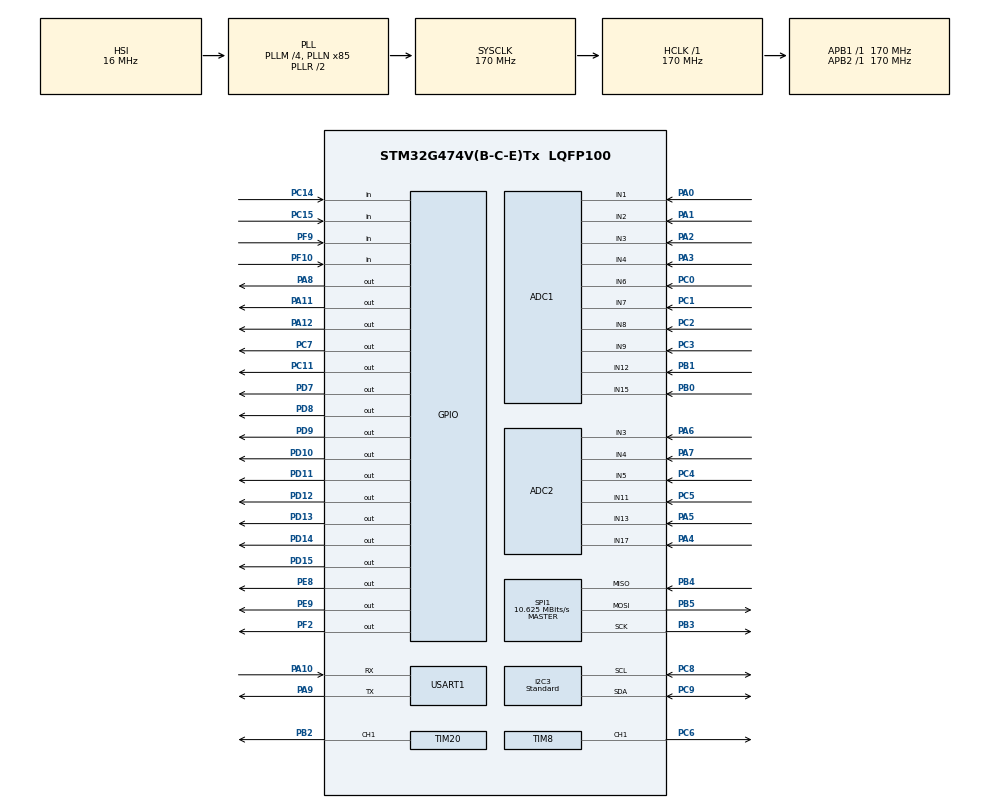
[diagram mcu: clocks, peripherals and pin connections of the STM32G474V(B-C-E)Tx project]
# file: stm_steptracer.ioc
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ADC1.Channel-0\#ChannelRegularConversion=ADC_CHANNEL_6
ADC1.Channel-1\#ChannelRegularConversion=ADC_CHANNEL_8
ADC1.Channel-2\#ChannelRegularConversion=ADC_CHANNEL_7
ADC1.Channel-3\#ChannelRegularConversion=ADC_CHANNEL_9
ADC1.Channel-4\#ChannelRegularConversion=ADC_CHANNEL_2
ADC1.Channel-5\#ChannelRegularConversion=ADC_CHANNEL_1
ADC1.Channel-6\#ChannelRegularConversion=ADC_CHANNEL_4
ADC1.Channel-7\#ChannelRegularConversion=ADC_CHANNEL_3
ADC1.Channel-8\#ChannelRegularConversion=ADC_CHANNEL_12
ADC1.Channel-9\#ChannelRegularConversion=ADC_CHANNEL_15
ADC1.EOCSelection=ADC_EOC_SEQ_CONV
ADC1.NbrOfConversion=10
ADC1.NbrOfConversionFlag=1
ADC1.OffsetNumber-0\#ChannelRegularConversion=ADC_OFFSET_NONE
ADC1.OffsetNumber-1\#ChannelRegularConversion=ADC_OFFSET_NONE
ADC1.OffsetNumber-2\#ChannelRegularConversion=ADC_OFFSET_NONE
ADC1.OffsetNumber-3\#ChannelRegularConversion=ADC_OFFSET_NONE
ADC1.OffsetNumber-4\#ChannelRegularConversion=ADC_OFFSET_NONE
ADC1.OffsetNumber-5\#ChannelRegularConversion=ADC_OFFSET_NONE
ADC1.OffsetNumber-6\#ChannelRegularConversion=ADC_OFFSET_NONE
ADC1.OffsetNumber-7\#ChannelRegularConversion=ADC_OFFSET_NONE
ADC1.OffsetNumber-8\#ChannelRegularConversion=ADC_OFFSET_NONE
ADC1.OffsetNumber-9\#ChannelRegularConversion=ADC_OFFSET_NONE
ADC1.Overrun=ADC_OVR_DATA_OVERWRITTEN
ADC1.Rank-0\#ChannelRegularConversion=1
ADC1.Rank-1\#ChannelRegularConversion=2
ADC1.Rank-2\#ChannelRegularConversion=3
ADC1.Rank-3\#ChannelRegularConversion=4
ADC1.Rank-4\#ChannelRegularConversion=5
ADC1.Rank-5\#ChannelRegularConversion=6
ADC1.Rank-6\#ChannelRegularConversion=7
ADC1.Rank-7\#ChannelRegularConversion=8
ADC1.Rank-8\#ChannelRegularConversion=9
ADC1.Rank-9\#ChannelRegularConversion=10
ADC1.SamplingTime-0\#ChannelRegularConversion=ADC_SAMPLETIME_47CYCLES_5
ADC1.SamplingTime-1\#ChannelRegularConversion=ADC_SAMPLETIME_47CYCLES_5
ADC1.SamplingTime-2\#ChannelRegularConversion=ADC_SAMPLETIME_47CYCLES_5
ADC1.SamplingTime-3\#ChannelRegularConversion=ADC_SAMPLETIME_47CYCLES_5
ADC1.SamplingTime-4\#ChannelRegularConversion=ADC_SAMPLETIME_47CYCLES_5
ADC1.SamplingTime-5\#ChannelRegularConversion=ADC_SAMPLETIME_47CYCLES_5
ADC1.SamplingTime-6\#ChannelRegularConversion=ADC_SAMPLETIME_47CYCLES_5
ADC1.SamplingTime-7\#ChannelRegularConversion=ADC_SAMPLETIME_47CYCLES_5
ADC1.SamplingTime-8\#ChannelRegularConversion=ADC_SAMPLETIME_47CYCLES_5
ADC1.SamplingTime-9\#ChannelRegularConversion=ADC_SAMPLETIME_47CYCLES_5
ADC1.master=1
ADC2.Channel-0\#ChannelRegularConversion=ADC_CHANNEL_13
ADC2.Channel-1\#ChannelRegularConversion=ADC_CHANNEL_17
ADC2.Channel-2\#ChannelRegularConversion=ADC_CHANNEL_4
ADC2.Channel-3\#ChannelRegularConversion=ADC_CHANNEL_3
ADC2.Channel-4\#ChannelRegularConversion=ADC_CHANNEL_11
ADC2.Channel-5\#ChannelRegularConversion=ADC_CHANNEL_5
ADC2.EOCSelection=ADC_EOC_SEQ_CONV
ADC2.NbrOfConversion=6
ADC2.NbrOfConversionFlag=1
ADC2.OffsetNumber-0\#ChannelRegularConversion=ADC_OFFSET_NONE
ADC2.OffsetNumber-1\#ChannelRegularConversion=ADC_OFFSET_NONE
ADC2.OffsetNumber-2\#ChannelRegularConversion=ADC_OFFSET_NONE
ADC2.OffsetNumber-3\#ChannelRegularConversion=ADC_OFFSET_NONE
ADC2.OffsetNumber-4\#ChannelRegularConversion=ADC_OFFSET_NONE
ADC2.OffsetNumber-5\#ChannelRegularConversion=ADC_OFFSET_NONE
ADC2.Overrun=ADC_OVR_DATA_OVERWRITTEN
ADC2.Rank-0\#ChannelRegularConversion=1
ADC2.Rank-1\#ChannelRegularConversion=2
ADC2.Rank-2\#ChannelRegularConversion=3
ADC2.Rank-3\#ChannelRegularConversion=4
ADC2.Rank-4\#ChannelRegularConversion=5
ADC2.Rank-5\#ChannelRegularConversion=6
ADC2.SamplingTime-0\#ChannelRegularConversion=ADC_SAMPLETIME_47CYCLES_5
ADC2.SamplingTime-1\#ChannelRegularConversion=ADC_SAMPLETIME_47CYCLES_5
ADC2.SamplingTime-2\#ChannelRegularConversion=ADC_SAMPLETIME_47CYCLES_5
ADC2.SamplingTime-3\#ChannelRegularConversion=ADC_SAMPLETIME_47CYCLES_5
ADC2.SamplingTime-4\#ChannelRegularConversion=ADC_SAMPLETIME_47CYCLES_5
ADC2.SamplingTime-5\#ChannelRegularConversion=ADC_SAMPLETIME_47CYCLES_5
Dma.ADC1.0.Direction=DMA_PERIPH_TO_MEMORY
Dma.ADC1.0.EventEnable=DISABLE
Dma.ADC1.0.Instance=DMA1_Channel1
Dma.ADC1.0.MemDataAlignment=DMA_MDATAALIGN_HALFWORD
Dma.ADC1.0.MemInc=DMA_MINC_ENABLE
Dma.ADC1.0.Mode=DMA_NORMAL
Dma.ADC1.0.PeriphDataAlignment=DMA_PDATAALIGN_HALFWORD
Dma.ADC1.0.PeriphInc=DMA_PINC_DISABLE
Dma.ADC1.0.Polarity=HAL_DMAMUX_REQ_GEN_RISING
Dma.ADC1.0.Priority=DMA_PRIORITY_HIGH
Dma.ADC1.0.RequestNumber=1
Dma.ADC1.0.SignalID=NONE
Dma.ADC1.0.SyncEnable=DISABLE
Dma.ADC1.0.SyncPolarity=HAL_DMAMUX_SYNC_NO_EVENT
Dma.ADC1.0.SyncRequestNumber=1
Dma.ADC1.0.SyncSignalID=NONE
Dma.ADC2.1.Direction=DMA_PERIPH_TO_MEMORY
Dma.ADC2.1.EventEnable=DISABLE
Dma.ADC2.1.Instance=DMA1_Channel2
Dma.ADC2.1.MemDataAlignment=DMA_MDATAALIGN_HALFWORD
Dma.ADC2.1.MemInc=DMA_MINC_ENABLE
Dma.ADC2.1.Mode=DMA_NORMAL
Dma.ADC2.1.PeriphDataAlignment=DMA_PDATAALIGN_HALFWORD
Dma.ADC2.1.PeriphInc=DMA_PINC_DISABLE
Dma.ADC2.1.Polarity=HAL_DMAMUX_REQ_GEN_RISING
Dma.ADC2.1.Priority=DMA_PRIORITY_LOW
Dma.ADC2.1.RequestNumber=1
Dma.ADC2.1.SignalID=NONE
Dma.ADC2.1.SyncEnable=DISABLE
Dma.ADC2.1.SyncPolarity=HAL_DMAMUX_SYNC_NO_EVENT
Dma.ADC2.1.SyncRequestNumber=1
Dma.ADC2.1.SyncSignalID=NONE
Dma.Request0=ADC1
Dma.Request1=ADC2
I2C3.I2C_Speed_Mode=I2C_Standard
I2C3.Timing=0x40B285C2
Mcu.Family=STM32G4
Mcu.Name=STM32G474V(B-C-E)Tx
Mcu.Package=LQFP100
NVIC.DMA1_Channel1_IRQn=true\:0\:0\:false\:false\:true\:false\:true\:true
NVIC.DMA1_Channel2_IRQn=true\:0\:0\:false\:false\:true\:false\:true\:true
NVIC.PriorityGroup=NVIC_PRIORITYGROUP_4
NVIC.TIM20_UP_IRQn=true\:0\:0\:false\:false\:true\:true\:true\:true
NVIC.TIM6_DAC_IRQn=true\:0\:0\:false\:false\:true\:true\:true\:true
NVIC.TIM7_DAC_IRQn=true\:0\:0\:true\:false\:true\:true\:true\:true
NVIC.TIM8_UP_IRQn=true\:0\:0\:false\:false\:true\:true\:true\:true
PA0.Mode=IN1-Single-Ended
PA0.Signal=ADC1_IN1
PA1.Mode=IN2-Single-Ended
PA1.Signal=ADC1_IN2
PA10.Mode=Asynchronous
PA10.Signal=USART1_RX
PA11.Signal=GPIO_Output
PA12.Signal=GPIO_Output
PA13.Mode=Serial_Wire
PA13.Signal=SYS_JTMS-SWDIO
PA14.Mode=Serial_Wire
PA14.Signal=SYS_JTCK-SWCLK
PA2.Mode=IN3-Single-Ended
PA2.Signal=ADC1_IN3
PA3.Mode=IN4-Single-Ended
PA3.Signal=ADC1_IN4
PA4.Mode=IN17-Single-Ended
PA4.Signal=ADC2_IN17
PA5.Mode=IN13-Single-Ended
PA5.Signal=ADC2_IN13
PA6.Mode=IN3-Single-Ended
PA6.Signal=ADC2_IN3
PA7.Mode=IN4-Single-Ended
PA7.Signal=ADC2_IN4
PA8.PinState=GPIO_PIN_SET
PA8.Signal=GPIO_Output
PA9.Mode=Asynchronous
PA9.Signal=USART1_TX
PB0.Mode=IN15-Single-Ended
PB0.Signal=ADC1_IN15
PB1.Mode=IN12-Single-Ended
PB1.Signal=ADC1_IN12
PB2.Signal=S_TIM20_CH1
PB3.Mode=Full_Duplex_Master
PB3.Signal=SPI1_SCK
PB4.Mode=Full_Duplex_Master
PB4.Signal=SPI1_MISO
PB5.Mode=Full_Duplex_Master
PB5.Signal=SPI1_MOSI
PC0.Mode=IN6-Single-Ended
PC0.Signal=ADC1_IN6
PC1.Mode=IN7-Single-Ended
PC1.Signal=ADC1_IN7
PC11.Signal=GPIO_Output
PC14-OSC32_IN.GPIO_PuPd=GPIO_PULLUP
PC14-OSC32_IN.Signal=GPIO_Input
PC15-OSC32_OUT.GPIO_PuPd=GPIO_PULLUP
PC15-OSC32_OUT.Signal=GPIO_Input
PC2.Mode=IN8-Single-Ended
PC2.Signal=ADC1_IN8
PC3.Mode=IN9-Single-Ended
PC3.Signal=ADC1_IN9
PC4.Mode=IN5-Single-Ended
PC4.Signal=ADC2_IN5
PC5.Mode=IN11-Single-Ended
PC5.Signal=ADC2_IN11
PC6.Signal=S_TIM8_CH1
PC7.Signal=GPIO_Output
PC8.Mode=I2C
PC8.Signal=I2C3_SCL
PC9.Mode=I2C
PC9.Signal=I2C3_SDA
PD10.GPIO_Speed=GPIO_SPEED_FREQ_MEDIUM
PD10.Signal=GPIO_Output
PD11.GPIO_Speed=GPIO_SPEED_FREQ_MEDIUM
PD11.Signal=GPIO_Output
PD12.GPIO_Speed=GPIO_SPEED_FREQ_MEDIUM
PD12.Signal=GPIO_Output
PD13.GPIO_Speed=GPIO_SPEED_FREQ_MEDIUM
PD13.Signal=GPIO_Output
PD14.GPIO_Speed=GPIO_SPEED_FREQ_MEDIUM
PD14.Signal=GPIO_Output
PD15.GPIO_Speed=GPIO_SPEED_FREQ_MEDIUM
PD15.Signal=GPIO_Output
PD7.GPIO_Speed=GPIO_SPEED_FREQ_HIGH
PD7.PinState=GPIO_PIN_SET
PD7.Signal=GPIO_Output
PD8.GPIO_Speed=GPIO_SPEED_FREQ_MEDIUM
PD8.Signal=GPIO_Output
PD9.GPIO_Speed=GPIO_SPEED_FREQ_MEDIUM
PD9.Signal=GPIO_Output
PE8.GPIO_Speed=GPIO_SPEED_FREQ_LOW
PE8.PinState=GPIO_PIN_SET
PE8.Signal=GPIO_Output
PE9.Signal=GPIO_Output
PF0-OSC_IN.Signal=RCC_OSC_IN
PF10.GPIO_PuPd=GPIO_PULLUP
PF10.Signal=GPIO_Input
PF2.Signal=GPIO_Output
PF9.GPIO_PuPd=GPIO_PULLUP
PF9.Signal=GPIO_Input
ProjectManager.HeapSize=0x200
ProjectManager.StackSize=0x400
ProjectManager.TargetToolchain=CMake
RCC.ADC12Freq_Value=170000000
RCC.ADC345Freq_Value=170000000
RCC.AHBFreq_Value=170000000
RCC.APB1Freq_Value=170000000
RCC.APB1TimFreq_Value=170000000
RCC.APB2Freq_Value=170000000
RCC.APB2TimFreq_Value=170000000
RCC.CortexFreq_Value=170000000
RCC.EXTERNAL_CLOCK_VALUE=12288000
RCC.HCLKFreq_Value=170000000
RCC.HSE_VALUE=20000000
RCC.HSI48_VALUE=48000000
RCC.HSI_VALUE=16000000
RCC.LSE_VALUE=32768
RCC.PLLM=RCC_PLLM_DIV4
RCC.PLLN=85
RCC.SYSCLKFreq_VALUE=170000000
RCC.SYSCLKSource=RCC_SYSCLKSOURCE_PLLCLK
RCC.USBFreq_Value=170000000
RCC.VCOOutputFreq_Value=340000000
SH.S_TIM20_CH1.0=TIM20_CH1,PWM Generation1 CH1
SH.S_TIM8_CH1.0=TIM8_CH1,PWM Generation1 CH1
SPI1.BaudRatePrescaler=SPI_BAUDRATEPRESCALER_16
SPI1.CalculateBaudRate=10.625 MBits/s
SPI1.DataSize=SPI_DATASIZE_8BIT
SPI1.Direction=SPI_DIRECTION_2LINES
SPI1.Mode=SPI_MODE_MASTER
SPI1.NSSPMode=SPI_NSS_PULSE_DISABLE
SPI1.VirtualType=VM_MASTER
TIM20.AutoReloadPreload=TIM_AUTORELOAD_PRELOAD_DISABLE
TIM20.Channel-PWM\ Generation1\ CH1=TIM_CHANNEL_1
TIM20.OC1Preload_PWM=DISABLE
TIM20.PeriodNoDither=999
TIM20.Prescaler=0
TIM20.PulseNoDither_1=500
TIM6.PeriodNoDither=14
TIM6.Prescaler=169
TIM7.PeriodNoDither=149
TIM7.Prescaler=169
TIM8.AutoReloadPreload=TIM_AUTORELOAD_PRELOAD_DISABLE
TIM8.Channel-PWM\ Generation1\ CH1=TIM_CHANNEL_1
TIM8.OC1Preload_PWM=DISABLE
TIM8.PeriodNoDither=999
TIM8.Prescaler=0
TIM8.PulseNoDither_1=500
USART1.VirtualMode-Asynchronous=VM_ASYNC
VP_SYS_VS_DBSignals.Mode=DisableDeadBatterySignals
VP_TIM20_VS_ClockSourceINT.Mode=Internal
VP_TIM6_VS_ClockSourceINT.Mode=Enable_Timer
VP_TIM7_VS_ClockSourceINT.Mode=Enable_Timer
VP_TIM8_VS_ClockSourceINT.Mode=Internal
board=custom

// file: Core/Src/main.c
/* USER CODE BEGIN Header */
/**
  ******************************************************************************
  * @file           : main.c
  * @brief          : Main program body
  ******************************************************************************
  * @attention
  *
  * Copyright (c) 2026 STMicroelectronics.
  * All rights reserved.
  *
  * This software is licensed under terms that can be found in the LICENSE file
  * in the root directory of this software component.
  * If no LICENSE file comes with this software, it is provided AS-IS.
  *
  ******************************************************************************
  */
/* USER CODE END Header */
#include "main.h"

/* USER CODE BEGIN Includes */
#include "Variable.h"
#include "sensor.h"
#include "menu.h"
#include "Motor.h"
#include "OLED.h"

/* USER CODE END Includes */

ADC_HandleTypeDef hadc1;
ADC_HandleTypeDef hadc2;
DMA_HandleTypeDef hdma_adc1;
DMA_HandleTypeDef hdma_adc2;

I2C_HandleTypeDef hi2c3;

SPI_HandleTypeDef hspi1;

TIM_HandleTypeDef htim6;
TIM_HandleTypeDef htim7;
TIM_HandleTypeDef htim8;
TIM_HandleTypeDef htim20;

UART_HandleTypeDef huart1;

void SystemClock_Config(void);
static void MX_GPIO_Init(void);
static void MX_DMA_Init(void);
static void MX_ADC1_Init(void);
static void MX_ADC2_Init(void);
static void MX_TIM8_Init(void);
static void MX_TIM20_Init(void);
static void MX_I2C3_Init(void);
static void MX_SPI1_Init(void);
static void MX_TIM6_Init(void);
static void MX_TIM7_Init(void);
static void MX_USART1_UART_Init(void);

int main(void)
{

  /* MCU Configuration--------------------------------------------------------*/

  /* Reset of all peripherals, Initializes the Flash interface and the Systick. */
  HAL_Init();

  /* Configure the system clock */
  SystemClock_Config();

  /* Initialize all configured peripherals */
  MX_GPIO_Init();
  MX_DMA_Init();
  MX_ADC1_Init();
  MX_ADC2_Init();
  MX_TIM8_Init();
  MX_TIM20_Init();
  MX_I2C3_Init();
  MX_SPI1_Init();
  MX_TIM6_Init();
  MX_TIM7_Init();
  MX_USART1_UART_Init();
  /* USER CODE BEGIN 2 */
  Variable_Init();
  sen_vari_init();
  Init_MOTOR();
  Menu_Init();

  /* USER CODE END 2 */

  /* Infinite loop */
  while (1)
  {

    /* USER CODE BEGIN 3 */
    Menu_Task();
  }
  /* USER CODE END 3 */
}

void SystemClock_Config(void)
{
  RCC_OscInitTypeDef RCC_OscInitStruct = {0};
  RCC_ClkInitTypeDef RCC_ClkInitStruct = {0};

  /** Configure the main internal regulator output voltage
  */
  HAL_PWREx_ControlVoltageScaling(PWR_REGULATOR_VOLTAGE_SCALE1_BOOST);

  /** Initializes the RCC Oscillators according to the specified parameters
  * in the RCC_OscInitTypeDef structure.
  */
  RCC_OscInitStruct.OscillatorType = RCC_OSCILLATORTYPE_HSI;
  RCC_OscInitStruct.HSIState = RCC_HSI_ON;
  RCC_OscInitStruct.HSICalibrationValue = RCC_HSICALIBRATION_DEFAULT;
  RCC_OscInitStruct.PLL.PLLState = RCC_PLL_ON;
  RCC_OscInitStruct.PLL.PLLSource = RCC_PLLSOURCE_HSI;
  RCC_OscInitStruct.PLL.PLLM = RCC_PLLM_DIV4;
  RCC_OscInitStruct.PLL.PLLN = 85;
  RCC_OscInitStruct.PLL.PLLP = RCC_PLLP_DIV2;
  RCC_OscInitStruct.PLL.PLLQ = RCC_PLLQ_DIV2;
  RCC_OscInitStruct.PLL.PLLR = RCC_PLLR_DIV2;
  if (HAL_RCC_OscConfig(&RCC_OscInitStruct) != HAL_OK)
  {
    Error_Handler();
  }

  /** Initializes the CPU, AHB and APB buses clocks
  */
  RCC_ClkInitStruct.ClockType = RCC_CLOCKTYPE_HCLK|RCC_CLOCKTYPE_SYSCLK
                              |RCC_CLOCKTYPE_PCLK1|RCC_CLOCKTYPE_PCLK2;
  RCC_ClkInitStruct.SYSCLKSource = RCC_SYSCLKSOURCE_PLLCLK;
  RCC_ClkInitStruct.AHBCLKDivider = RCC_SYSCLK_DIV1;
  RCC_ClkInitStruct.APB1CLKDivider = RCC_HCLK_DIV1;
  RCC_ClkInitStruct.APB2CLKDivider = RCC_HCLK_DIV1;

  if (HAL_RCC_ClockConfig(&RCC_ClkInitStruct, FLASH_LATENCY_4) != HAL_OK)
  {
    Error_Handler();
  }
}

static void MX_ADC1_Init(void)
{

  ADC_MultiModeTypeDef multimode = {0};
  ADC_ChannelConfTypeDef sConfig = {0};

  /** Common config
  */
  hadc1.Instance = ADC1;
  hadc1.Init.ClockPrescaler = ADC_CLOCK_SYNC_PCLK_DIV4;
  hadc1.Init.Resolution = ADC_RESOLUTION_12B;
  hadc1.Init.DataAlign = ADC_DATAALIGN_RIGHT;
  hadc1.Init.GainCompensation = 0;
  hadc1.Init.ScanConvMode = ADC_SCAN_ENABLE;
  hadc1.Init.EOCSelection = ADC_EOC_SEQ_CONV;
  hadc1.Init.LowPowerAutoWait = DISABLE;
  hadc1.Init.ContinuousConvMode = DISABLE;
  hadc1.Init.NbrOfConversion = 10;
  hadc1.Init.DiscontinuousConvMode = DISABLE;
  hadc1.Init.ExternalTrigConv = ADC_SOFTWARE_START;
  hadc1.Init.ExternalTrigConvEdge = ADC_EXTERNALTRIGCONVEDGE_NONE;
  hadc1.Init.DMAContinuousRequests = DISABLE;
  hadc1.Init.Overrun = ADC_OVR_DATA_OVERWRITTEN;
  hadc1.Init.OversamplingMode = DISABLE;
  if (HAL_ADC_Init(&hadc1) != HAL_OK)
  {
    Error_Handler();
  }

  /** Configure the ADC multi-mode
  */
  multimode.Mode = ADC_MODE_INDEPENDENT;
  if (HAL_ADCEx_MultiModeConfigChannel(&hadc1, &multimode) != HAL_OK)
  {
    Error_Handler();
  }

  /** Configure Regular Channel
  */
  sConfig.Channel = ADC_CHANNEL_6;
  sConfig.Rank = ADC_REGULAR_RANK_1;
  sConfig.SamplingTime = ADC_SAMPLETIME_47CYCLES_5;
  sConfig.SingleDiff = ADC_SINGLE_ENDED;
  sConfig.OffsetNumber = ADC_OFFSET_NONE;
  sConfig.Offset = 0;
  if (HAL_ADC_ConfigChannel(&hadc1, &sConfig) != HAL_OK)
  {
    Error_Handler();
  }

  /** Configure Regular Channel
  */
  sConfig.Channel = ADC_CHANNEL_8;
  sConfig.Rank = ADC_REGULAR_RANK_2;
  if (HAL_ADC_ConfigChannel(&hadc1, &sConfig) != HAL_OK)
  {
    Error_Handler();
  }

  /** Configure Regular Channel
  */
  sConfig.Channel = ADC_CHANNEL_7;
  sConfig.Rank = ADC_REGULAR_RANK_3;
  if (HAL_ADC_ConfigChannel(&hadc1, &sConfig) != HAL_OK)
  {
    Error_Handler();
  }

  /** Configure Regular Channel
  */
  sConfig.Channel = ADC_CHANNEL_9;
  sConfig.Rank = ADC_REGULAR_RANK_4;
  if (HAL_ADC_ConfigChannel(&hadc1, &sConfig) != HAL_OK)
  {
    Error_Handler();
  }

  /** Configure Regular Channel
  */
  sConfig.Channel = ADC_CHANNEL_2;
  sConfig.Rank = ADC_REGULAR_RANK_5;
  if (HAL_ADC_ConfigChannel(&hadc1, &sConfig) != HAL_OK)
  {
    Error_Handler();
  }

  /** Configure Regular Channel
  */
  sConfig.Channel = ADC_CHANNEL_1;
  sConfig.Rank = ADC_REGULAR_RANK_6;
  if (HAL_ADC_ConfigChannel(&hadc1, &sConfig) != HAL_OK)
  {
    Error_Handler();
  }

  /** Configure Regular Channel
  */
  sConfig.Channel = ADC_CHANNEL_4;
  sConfig.Rank = ADC_REGULAR_RANK_7;
  if (HAL_ADC_ConfigChannel(&hadc1, &sConfig) != HAL_OK)
  {
    Error_Handler();
  }

  /** Configure Regular Channel
  */
  sConfig.Channel = ADC_CHANNEL_3;
  sConfig.Rank = ADC_REGULAR_RANK_8;
  if (HAL_ADC_ConfigChannel(&hadc1, &sConfig) != HAL_OK)
  {
    Error_Handler();
  }

  /** Configure Regular Channel
  */
  sConfig.Channel = ADC_CHANNEL_12;
  sConfig.Rank = ADC_REGULAR_RANK_9;
  if (HAL_ADC_ConfigChannel(&hadc1, &sConfig) != HAL_OK)
  {
    Error_Handler();
  }

  /** Configure Regular Channel
  */
  sConfig.Channel = ADC_CHANNEL_15;
  sConfig.Rank = ADC_REGULAR_RANK_10;
  if (HAL_ADC_ConfigChannel(&hadc1, &sConfig) != HAL_OK)
  {
    Error_Handler();
  }

}

static void MX_ADC2_Init(void)
{

  ADC_ChannelConfTypeDef sConfig = {0};

  /** Common config
  */
  hadc2.Instance = ADC2;
  hadc2.Init.ClockPrescaler = ADC_CLOCK_SYNC_PCLK_DIV4;
  hadc2.Init.Resolution = ADC_RESOLUTION_12B;
  hadc2.Init.DataAlign = ADC_DATAALIGN_RIGHT;
  hadc2.Init.GainCompensation = 0;
  hadc2.Init.ScanConvMode = ADC_SCAN_ENABLE;
  hadc2.Init.EOCSelection = ADC_EOC_SEQ_CONV;
  hadc2.Init.LowPowerAutoWait = DISABLE;
  hadc2.Init.ContinuousConvMode = DISABLE;
  hadc2.Init.NbrOfConversion = 6;
  hadc2.Init.DiscontinuousConvMode = DISABLE;
  hadc2.Init.ExternalTrigConv = ADC_SOFTWARE_START;
  hadc2.Init.ExternalTrigConvEdge = ADC_EXTERNALTRIGCONVEDGE_NONE;
  hadc2.Init.DMAContinuousRequests = DISABLE;
  hadc2.Init.Overrun = ADC_OVR_DATA_OVERWRITTEN;
  hadc2.Init.OversamplingMode = DISABLE;
  if (HAL_ADC_Init(&hadc2) != HAL_OK)
  {
    Error_Handler();
  }

  /** Configure Regular Channel
  */
  sConfig.Channel = ADC_CHANNEL_13;
  sConfig.Rank = ADC_REGULAR_RANK_1;
  sConfig.SamplingTime = ADC_SAMPLETIME_47CYCLES_5;
  sConfig.SingleDiff = ADC_SINGLE_ENDED;
  sConfig.OffsetNumber = ADC_OFFSET_NONE;
  sConfig.Offset = 0;
  if (HAL_ADC_ConfigChannel(&hadc2, &sConfig) != HAL_OK)
  {
    Error_Handler();
  }

  /** Configure Regular Channel
  */
  sConfig.Channel = ADC_CHANNEL_17;
  sConfig.Rank = ADC_REGULAR_RANK_2;
  if (HAL_ADC_ConfigChannel(&hadc2, &sConfig) != HAL_OK)
  {
    Error_Handler();
  }

  /** Configure Regular Channel
  */
  sConfig.Channel = ADC_CHANNEL_4;
  sConfig.Rank = ADC_REGULAR_RANK_3;
  if (HAL_ADC_ConfigChannel(&hadc2, &sConfig) != HAL_OK)
  {
    Error_Handler();
  }

  /** Configure Regular Channel
  */
  sConfig.Channel = ADC_CHANNEL_3;
  sConfig.Rank = ADC_REGULAR_RANK_4;
  if (HAL_ADC_ConfigChannel(&hadc2, &sConfig) != HAL_OK)
  {
    Error_Handler();
  }

  /** Configure Regular Channel
  */
  sConfig.Channel = ADC_CHANNEL_11;
  sConfig.Rank = ADC_REGULAR_RANK_5;
  if (HAL_ADC_ConfigChannel(&hadc2, &sConfig) != HAL_OK)
  {
    Error_Handler();
  }

  /** Configure Regular Channel
  */
  sConfig.Channel = ADC_CHANNEL_5;
  sConfig.Rank = ADC_REGULAR_RANK_6;
  if (HAL_ADC_ConfigChannel(&hadc2, &sConfig) != HAL_OK)
  {
    Error_Handler();
  }

}

static void MX_I2C3_Init(void)
{

  hi2c3.Instance = I2C3;
  hi2c3.Init.Timing = 0x40B285C2;
  hi2c3.Init.OwnAddress1 = 0;
  hi2c3.Init.AddressingMode = I2C_ADDRESSINGMODE_7BIT;
  hi2c3.Init.DualAddressMode = I2C_DUALADDRESS_DISABLE;
  hi2c3.Init.OwnAddress2 = 0;
  hi2c3.Init.OwnAddress2Masks = I2C_OA2_NOMASK;
  hi2c3.Init.GeneralCallMode = I2C_GENERALCALL_DISABLE;
  hi2c3.Init.NoStretchMode = I2C_NOSTRETCH_DISABLE;
  if (HAL_I2C_Init(&hi2c3) != HAL_OK)
  {
    Error_Handler();
  }

  /** Configure Analogue filter
  */
  if (HAL_I2CEx_ConfigAnalogFilter(&hi2c3, I2C_ANALOGFILTER_ENABLE) != HAL_OK)
  {
    Error_Handler();
  }

  /** Configure Digital filter
  */
  if (HAL_I2CEx_ConfigDigitalFilter(&hi2c3, 0) != HAL_OK)
  {
    Error_Handler();
  }

}

static void MX_SPI1_Init(void)
{

  /* SPI1 parameter configuration*/
  hspi1.Instance = SPI1;
  hspi1.Init.Mode = SPI_MODE_MASTER;
  hspi1.Init.Direction = SPI_DIRECTION_2LINES;
  hspi1.Init.DataSize = SPI_DATASIZE_8BIT;
  hspi1.Init.CLKPolarity = SPI_POLARITY_LOW;
  hspi1.Init.CLKPhase = SPI_PHASE_1EDGE;
  hspi1.Init.NSS = SPI_NSS_SOFT;
  hspi1.Init.BaudRatePrescaler = SPI_BAUDRATEPRESCALER_16;
  hspi1.Init.FirstBit = SPI_FIRSTBIT_MSB;
  hspi1.Init.TIMode = SPI_TIMODE_DISABLE;
  hspi1.Init.CRCCalculation = SPI_CRCCALCULATION_DISABLE;
  hspi1.Init.CRCPolynomial = 7;
  hspi1.Init.CRCLength = SPI_CRC_LENGTH_DATASIZE;
  hspi1.Init.NSSPMode = SPI_NSS_PULSE_DISABLE;
  if (HAL_SPI_Init(&hspi1) != HAL_OK)
  {
    Error_Handler();
  }

}

static void MX_TIM6_Init(void)
{

  TIM_MasterConfigTypeDef sMasterConfig = {0};

  htim6.Instance = TIM6;
  htim6.Init.Prescaler = 169;
  htim6.Init.CounterMode = TIM_COUNTERMODE_UP;
  htim6.Init.Period = 14;
  htim6.Init.AutoReloadPreload = TIM_AUTORELOAD_PRELOAD_DISABLE;
  if (HAL_TIM_Base_Init(&htim6) != HAL_OK)
  {
    Error_Handler();
  }
  sMasterConfig.MasterOutputTrigger = TIM_TRGO_RESET;
  sMasterConfig.MasterSlaveMode = TIM_MASTERSLAVEMODE_DISABLE;
  if (HAL_TIMEx_MasterConfigSynchronization(&htim6, &sMasterConfig) != HAL_OK)
  {
    Error_Handler();
  }

}

static void MX_TIM7_Init(void)
{

  TIM_MasterConfigTypeDef sMasterConfig = {0};

  htim7.Instance = TIM7;
  htim7.Init.Prescaler = 169;
  htim7.Init.CounterMode = TIM_COUNTERMODE_UP;
  htim7.Init.Period = 149;
  htim7.Init.AutoReloadPreload = TIM_AUTORELOAD_PRELOAD_DISABLE;
  if (HAL_TIM_Base_Init(&htim7) != HAL_OK)
  {
    Error_Handler();
  }
  sMasterConfig.MasterOutputTrigger = TIM_TRGO_RESET;
  sMasterConfig.MasterSlaveMode = TIM_MASTERSLAVEMODE_DISABLE;
  if (HAL_TIMEx_MasterConfigSynchronization(&htim7, &sMasterConfig) != HAL_OK)
  {
    Error_Handler();
  }

}

static void MX_TIM8_Init(void)
{

  TIM_ClockConfigTypeDef sClockSourceConfig = {0};
  TIM_MasterConfigTypeDef sMasterConfig = {0};
  TIM_OC_InitTypeDef sConfigOC = {0};
  TIM_BreakDeadTimeConfigTypeDef sBreakDeadTimeConfig = {0};

  htim8.Instance = TIM8;
  htim8.Init.Prescaler = 0;
  htim8.Init.CounterMode = TIM_COUNTERMODE_UP;
  htim8.Init.Period = 999;
  htim8.Init.ClockDivision = TIM_CLOCKDIVISION_DIV1;
  htim8.Init.RepetitionCounter = 0;
  htim8.Init.AutoReloadPreload = TIM_AUTORELOAD_PRELOAD_DISABLE;
  if (HAL_TIM_Base_Init(&htim8) != HAL_OK)
  {
    Error_Handler();
  }
  sClockSourceConfig.ClockSource = TIM_CLOCKSOURCE_INTERNAL;
  if (HAL_TIM_ConfigClockSource(&htim8, &sClockSourceConfig) != HAL_OK)
  {
    Error_Handler();
  }
  if (HAL_TIM_PWM_Init(&htim8) != HAL_OK)
  {
    Error_Handler();
  }
  sMasterConfig.MasterOutputTrigger = TIM_TRGO_RESET;
  sMasterConfig.MasterOutputTrigger2 = TIM_TRGO2_RESET;
  sMasterConfig.MasterSlaveMode = TIM_MASTERSLAVEMODE_DISABLE;
  if (HAL_TIMEx_MasterConfigSynchronization(&htim8, &sMasterConfig) != HAL_OK)
  {
    Error_Handler();
  }
  sConfigOC.OCMode = TIM_OCMODE_PWM1;
  sConfigOC.Pulse = 500;
  sConfigOC.OCPolarity = TIM_OCPOLARITY_HIGH;
  sConfigOC.OCNPolarity = TIM_OCNPOLARITY_HIGH;
  sConfigOC.OCFastMode = TIM_OCFAST_DISABLE;
  sConfigOC.OCIdleState = TIM_OCIDLESTATE_RESET;
  sConfigOC.OCNIdleState = TIM_OCNIDLESTATE_RESET;
  if (HAL_TIM_PWM_ConfigChannel(&htim8, &sConfigOC, TIM_CHANNEL_1) != HAL_OK)
  {
    Error_Handler();
  }
  __HAL_TIM_DISABLE_OCxPRELOAD(&htim8, TIM_CHANNEL_1);
  sBreakDeadTimeConfig.OffStateRunMode = TIM_OSSR_DISABLE;
  sBreakDeadTimeConfig.OffStateIDLEMode = TIM_OSSI_DISABLE;
  sBreakDeadTimeConfig.LockLevel = TIM_LOCKLEVEL_OFF;
  sBreakDeadTimeConfig.DeadTime = 0;
  sBreakDeadTimeConfig.BreakState = TIM_BREAK_DISABLE;
  sBreakDeadTimeConfig.BreakPolarity = TIM_BREAKPOLARITY_HIGH;
  sBreakDeadTimeConfig.BreakFilter = 0;
  sBreakDeadTimeConfig.BreakAFMode = TIM_BREAK_AFMODE_INPUT;
  sBreakDeadTimeConfig.Break2State = TIM_BREAK2_DISABLE;
  sBreakDeadTimeConfig.Break2Polarity = TIM_BREAK2POLARITY_HIGH;
  sBreakDeadTimeConfig.Break2Filter = 0;
  sBreakDeadTimeConfig.Break2AFMode = TIM_BREAK_AFMODE_INPUT;
  sBreakDeadTimeConfig.AutomaticOutput = TIM_AUTOMATICOUTPUT_DISABLE;
  if (HAL_TIMEx_ConfigBreakDeadTime(&htim8, &sBreakDeadTimeConfig) != HAL_OK)
  {
    Error_Handler();
  }
  HAL_TIM_MspPostInit(&htim8);

}

static void MX_TIM20_Init(void)
{

  TIM_ClockConfigTypeDef sClockSourceConfig = {0};
  TIM_MasterConfigTypeDef sMasterConfig = {0};
  TIM_OC_InitTypeDef sConfigOC = {0};
  TIM_BreakDeadTimeConfigTypeDef sBreakDeadTimeConfig = {0};

  htim20.Instance = TIM20;
  htim20.Init.Prescaler = 0;
  htim20.Init.CounterMode = TIM_COUNTERMODE_UP;
  htim20.Init.Period = 999;
  htim20.Init.ClockDivision = TIM_CLOCKDIVISION_DIV1;
  htim20.Init.RepetitionCounter = 0;
  htim20.Init.AutoReloadPreload = TIM_AUTORELOAD_PRELOAD_DISABLE;
  if (HAL_TIM_Base_Init(&htim20) != HAL_OK)
  {
    Error_Handler();
  }
  sClockSourceConfig.ClockSource = TIM_CLOCKSOURCE_INTERNAL;
  if (HAL_TIM_ConfigClockSource(&htim20, &sClockSourceConfig) != HAL_OK)
  {
    Error_Handler();
  }
  if (HAL_TIM_PWM_Init(&htim20) != HAL_OK)
  {
    Error_Handler();
  }
  sMasterConfig.MasterOutputTrigger = TIM_TRGO_RESET;
  sMasterConfig.MasterOutputTrigger2 = TIM_TRGO2_RESET;
  sMasterConfig.MasterSlaveMode = TIM_MASTERSLAVEMODE_DISABLE;
  if (HAL_TIMEx_MasterConfigSynchronization(&htim20, &sMasterConfig) != HAL_OK)
  {
    Error_Handler();
  }
  sConfigOC.OCMode = TIM_OCMODE_PWM1;
  sConfigOC.Pulse = 500;
  sConfigOC.OCPolarity = TIM_OCPOLARITY_HIGH;
  sConfigOC.OCNPolarity = TIM_OCNPOLARITY_HIGH;
  sConfigOC.OCFastMode = TIM_OCFAST_DISABLE;
  sConfigOC.OCIdleState = TIM_OCIDLESTATE_RESET;
  sConfigOC.OCNIdleState = TIM_OCNIDLESTATE_RESET;
  if (HAL_TIM_PWM_ConfigChannel(&htim20, &sConfigOC, TIM_CHANNEL_1) != HAL_OK)
  {
    Error_Handler();
  }
  __HAL_TIM_DISABLE_OCxPRELOAD(&htim20, TIM_CHANNEL_1);
  sBreakDeadTimeConfig.OffStateRunMode = TIM_OSSR_DISABLE;
  sBreakDeadTimeConfig.OffStateIDLEMode = TIM_OSSI_DISABLE;
  sBreakDeadTimeConfig.LockLevel = TIM_LOCKLEVEL_OFF;
  sBreakDeadTimeConfig.DeadTime = 0;
  sBreakDeadTimeConfig.BreakState = TIM_BREAK_DISABLE;
  sBreakDeadTimeConfig.BreakPolarity = TIM_BREAKPOLARITY_HIGH;
  sBreakDeadTimeConfig.BreakFilter = 0;
  sBreakDeadTimeConfig.BreakAFMode = TIM_BREAK_AFMODE_INPUT;
  sBreakDeadTimeConfig.Break2State = TIM_BREAK2_DISABLE;
  sBreakDeadTimeConfig.Break2Polarity = TIM_BREAK2POLARITY_HIGH;
  sBreakDeadTimeConfig.Break2Filter = 0;
  sBreakDeadTimeConfig.Break2AFMode = TIM_BREAK_AFMODE_INPUT;
  sBreakDeadTimeConfig.AutomaticOutput = TIM_AUTOMATICOUTPUT_DISABLE;
  if (HAL_TIMEx_ConfigBreakDeadTime(&htim20, &sBreakDeadTimeConfig) != HAL_OK)
  {
    Error_Handler();
  }
  HAL_TIM_MspPostInit(&htim20);

}

static void MX_USART1_UART_Init(void)
{

  huart1.Instance = USART1;
  huart1.Init.BaudRate = 115200;
  huart1.Init.WordLength = UART_WORDLENGTH_8B;
  huart1.Init.StopBits = UART_STOPBITS_1;
  huart1.Init.Parity = UART_PARITY_NONE;
  huart1.Init.Mode = UART_MODE_TX_RX;
  huart1.Init.HwFlowCtl = UART_HWCONTROL_NONE;
  huart1.Init.OverSampling = UART_OVERSAMPLING_16;
  huart1.Init.OneBitSampling = UART_ONE_BIT_SAMPLE_DISABLE;
  huart1.Init.ClockPrescaler = UART_PRESCALER_DIV1;
  huart1.AdvancedInit.AdvFeatureInit = UART_ADVFEATURE_NO_INIT;
  if (HAL_UART_Init(&huart1) != HAL_OK)
  {
    Error_Handler();
  }
  if (HAL_UARTEx_SetTxFifoThreshold(&huart1, UART_TXFIFO_THRESHOLD_1_8) != HAL_OK)
  {
    Error_Handler();
  }
  if (HAL_UARTEx_SetRxFifoThreshold(&huart1, UART_RXFIFO_THRESHOLD_1_8) != HAL_OK)
  {
    Error_Handler();
  }
  if (HAL_UARTEx_DisableFifoMode(&huart1) != HAL_OK)
  {
    Error_Handler();
  }

}

static void MX_DMA_Init(void)
{

  /* DMA controller clock enable */
  __HAL_RCC_DMAMUX1_CLK_ENABLE();
  __HAL_RCC_DMA1_CLK_ENABLE();

  /* DMA interrupt init */
  /* DMA1_Channel1_IRQn interrupt configuration */
  HAL_NVIC_SetPriority(DMA1_Channel1_IRQn, 0, 0);
  HAL_NVIC_EnableIRQ(DMA1_Channel1_IRQn);
  /* DMA1_Channel2_IRQn interrupt configuration */
  HAL_NVIC_SetPriority(DMA1_Channel2_IRQn, 0, 0);
  HAL_NVIC_EnableIRQ(DMA1_Channel2_IRQn);

}

static void MX_GPIO_Init(void)
{
  GPIO_InitTypeDef GPIO_InitStruct = {0};

  /* GPIO Ports Clock Enable */
  __HAL_RCC_GPIOC_CLK_ENABLE();
  __HAL_RCC_GPIOF_CLK_ENABLE();
  __HAL_RCC_GPIOA_CLK_ENABLE();
  __HAL_RCC_GPIOB_CLK_ENABLE();
  __HAL_RCC_GPIOE_CLK_ENABLE();
  __HAL_RCC_GPIOD_CLK_ENABLE();

  /*Configure GPIO pin Output Level */
  HAL_GPIO_WritePin(GPIOF, GPIO_PIN_2, GPIO_PIN_RESET);

  /*Configure GPIO pin Output Level */
  HAL_GPIO_WritePin(GPIOE, GPIO_PIN_8, GPIO_PIN_SET);

  /*Configure GPIO pin Output Level */
  HAL_GPIO_WritePin(GPIOE, GPIO_PIN_9, GPIO_PIN_RESET);

  /*Configure GPIO pin Output Level */
  HAL_GPIO_WritePin(GPIOD, GPIO_PIN_8|GPIO_PIN_9|GPIO_PIN_10|GPIO_PIN_11
                          |GPIO_PIN_12|GPIO_PIN_13|GPIO_PIN_14|GPIO_PIN_15, GPIO_PIN_RESET);

  /*Configure GPIO pin Output Level */
  HAL_GPIO_WritePin(GPIOC, GPIO_PIN_7|GPIO_PIN_11, GPIO_PIN_RESET);

  /*Configure GPIO pin Output Level */
  HAL_GPIO_WritePin(GPIOA, GPIO_PIN_8, GPIO_PIN_SET);

  /*Configure GPIO pin Output Level */
  HAL_GPIO_WritePin(GPIOA, GPIO_PIN_11|GPIO_PIN_12, GPIO_PIN_RESET);

  /*Configure GPIO pin Output Level */
  HAL_GPIO_WritePin(GPIOD, GPIO_PIN_7, GPIO_PIN_SET);

  /*Configure GPIO pins : PC14 PC15 */
  GPIO_InitStruct.Pin = GPIO_PIN_14|GPIO_PIN_15;
  GPIO_InitStruct.Mode = GPIO_MODE_INPUT;
  GPIO_InitStruct.Pull = GPIO_PULLUP;
  HAL_GPIO_Init(GPIOC, &GPIO_InitStruct);

  /*Configure GPIO pins : PF9 PF10 */
  GPIO_InitStruct.Pin = GPIO_PIN_9|GPIO_PIN_10;
  GPIO_InitStruct.Mode = GPIO_MODE_INPUT;
  GPIO_InitStruct.Pull = GPIO_PULLUP;
  HAL_GPIO_Init(GPIOF, &GPIO_InitStruct);

  /*Configure GPIO pin : PF2 */
  GPIO_InitStruct.Pin = GPIO_PIN_2;
  GPIO_InitStruct.Mode = GPIO_MODE_OUTPUT_PP;
  GPIO_InitStruct.Pull = GPIO_NOPULL;
  GPIO_InitStruct.Speed = GPIO_SPEED_FREQ_LOW;
  HAL_GPIO_Init(GPIOF, &GPIO_InitStruct);

  /*Configure GPIO pins : PE8 PE9 */
  GPIO_InitStruct.Pin = GPIO_PIN_8|GPIO_PIN_9;
  GPIO_InitStruct.Mode = GPIO_MODE_OUTPUT_PP;
  GPIO_InitStruct.Pull = GPIO_NOPULL;
  GPIO_InitStruct.Speed = GPIO_SPEED_FREQ_LOW;
  HAL_GPIO_Init(GPIOE, &GPIO_InitStruct);

  /*Configure GPIO pins : PD8 PD9 PD10 PD11
                           PD12 PD13 PD14 PD15 */
  GPIO_InitStruct.Pin = GPIO_PIN_8|GPIO_PIN_9|GPIO_PIN_10|GPIO_PIN_11
                          |GPIO_PIN_12|GPIO_PIN_13|GPIO_PIN_14|GPIO_PIN_15;
  GPIO_InitStruct.Mode = GPIO_MODE_OUTPUT_PP;
  GPIO_InitStruct.Pull = GPIO_NOPULL;
  GPIO_InitStruct.Speed = GPIO_SPEED_FREQ_MEDIUM;
  HAL_GPIO_Init(GPIOD, &GPIO_InitStruct);

  /*Configure GPIO pins : PC7 PC11 */
  GPIO_InitStruct.Pin = GPIO_PIN_7|GPIO_PIN_11;
  GPIO_InitStruct.Mode = GPIO_MODE_OUTPUT_PP;
  GPIO_InitStruct.Pull = GPIO_NOPULL;
  GPIO_InitStruct.Speed = GPIO_SPEED_FREQ_LOW;
  HAL_GPIO_Init(GPIOC, &GPIO_InitStruct);

  /*Configure GPIO pins : PA8 PA11 PA12 */
  GPIO_InitStruct.Pin = GPIO_PIN_8|GPIO_PIN_11|GPIO_PIN_12;
  GPIO_InitStruct.Mode = GPIO_MODE_OUTPUT_PP;
  GPIO_InitStruct.Pull = GPIO_NOPULL;
  GPIO_InitStruct.Speed = GPIO_SPEED_FREQ_LOW;
  HAL_GPIO_Init(GPIOA, &GPIO_InitStruct);

  /*Configure GPIO pin : PD7 */
  GPIO_InitStruct.Pin = GPIO_PIN_7;
  GPIO_InitStruct.Mode = GPIO_MODE_OUTPUT_PP;
  GPIO_InitStruct.Pull = GPIO_NOPULL;
  GPIO_InitStruct.Speed = GPIO_SPEED_FREQ_HIGH;
  HAL_GPIO_Init(GPIOD, &GPIO_InitStruct);

}

void Error_Handler(void)
{
  __disable_irq();
  while (1)
  {
  }
}
